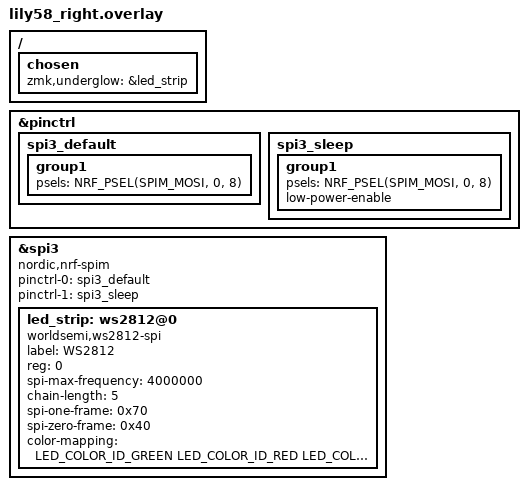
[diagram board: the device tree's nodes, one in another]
#include <dt-bindings/led/led.h>
// Configuración de pines SPI para los LEDs
&pinctrl {
    spi3_default: spi3_default {
        group1 {
            psels = <NRF_PSEL(SPIM_MOSI, 0, 8)>;
        };
    };

    spi3_sleep: spi3_sleep {
        group1 {
            psels = <NRF_PSEL(SPIM_MOSI, 0, 8)>;
            low-power-enable;
        };
    };
};

// Activación de la tira LED
&spi3 {
    compatible = "nordic,nrf-spim";
    status = "okay";

    pinctrl-0 = <&spi3_default>;
    pinctrl-1 = <&spi3_sleep>;
    pinctrl-names = "default", "sleep";

    led_strip: ws2812@0 {
        compatible = "worldsemi,ws2812-spi";
        label = "WS2812";
        reg = <0>;
        spi-max-frequency = <4000000>;
        
        /* === AQUÍ ESTÁ TU PRUEBA DE 5 LEDS === */
        chain-length = <5>; 
        
        spi-one-frame = <0x70>;
        spi-zero-frame = <0x40>;
        color-mapping = <LED_COLOR_ID_GREEN LED_COLOR_ID_RED LED_COLOR_ID_BLUE>;
    };
};

// Le decimos al teclado que use esta tira como underglow
/ {
    chosen {
        zmk,underglow = &led_strip;
    };
};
